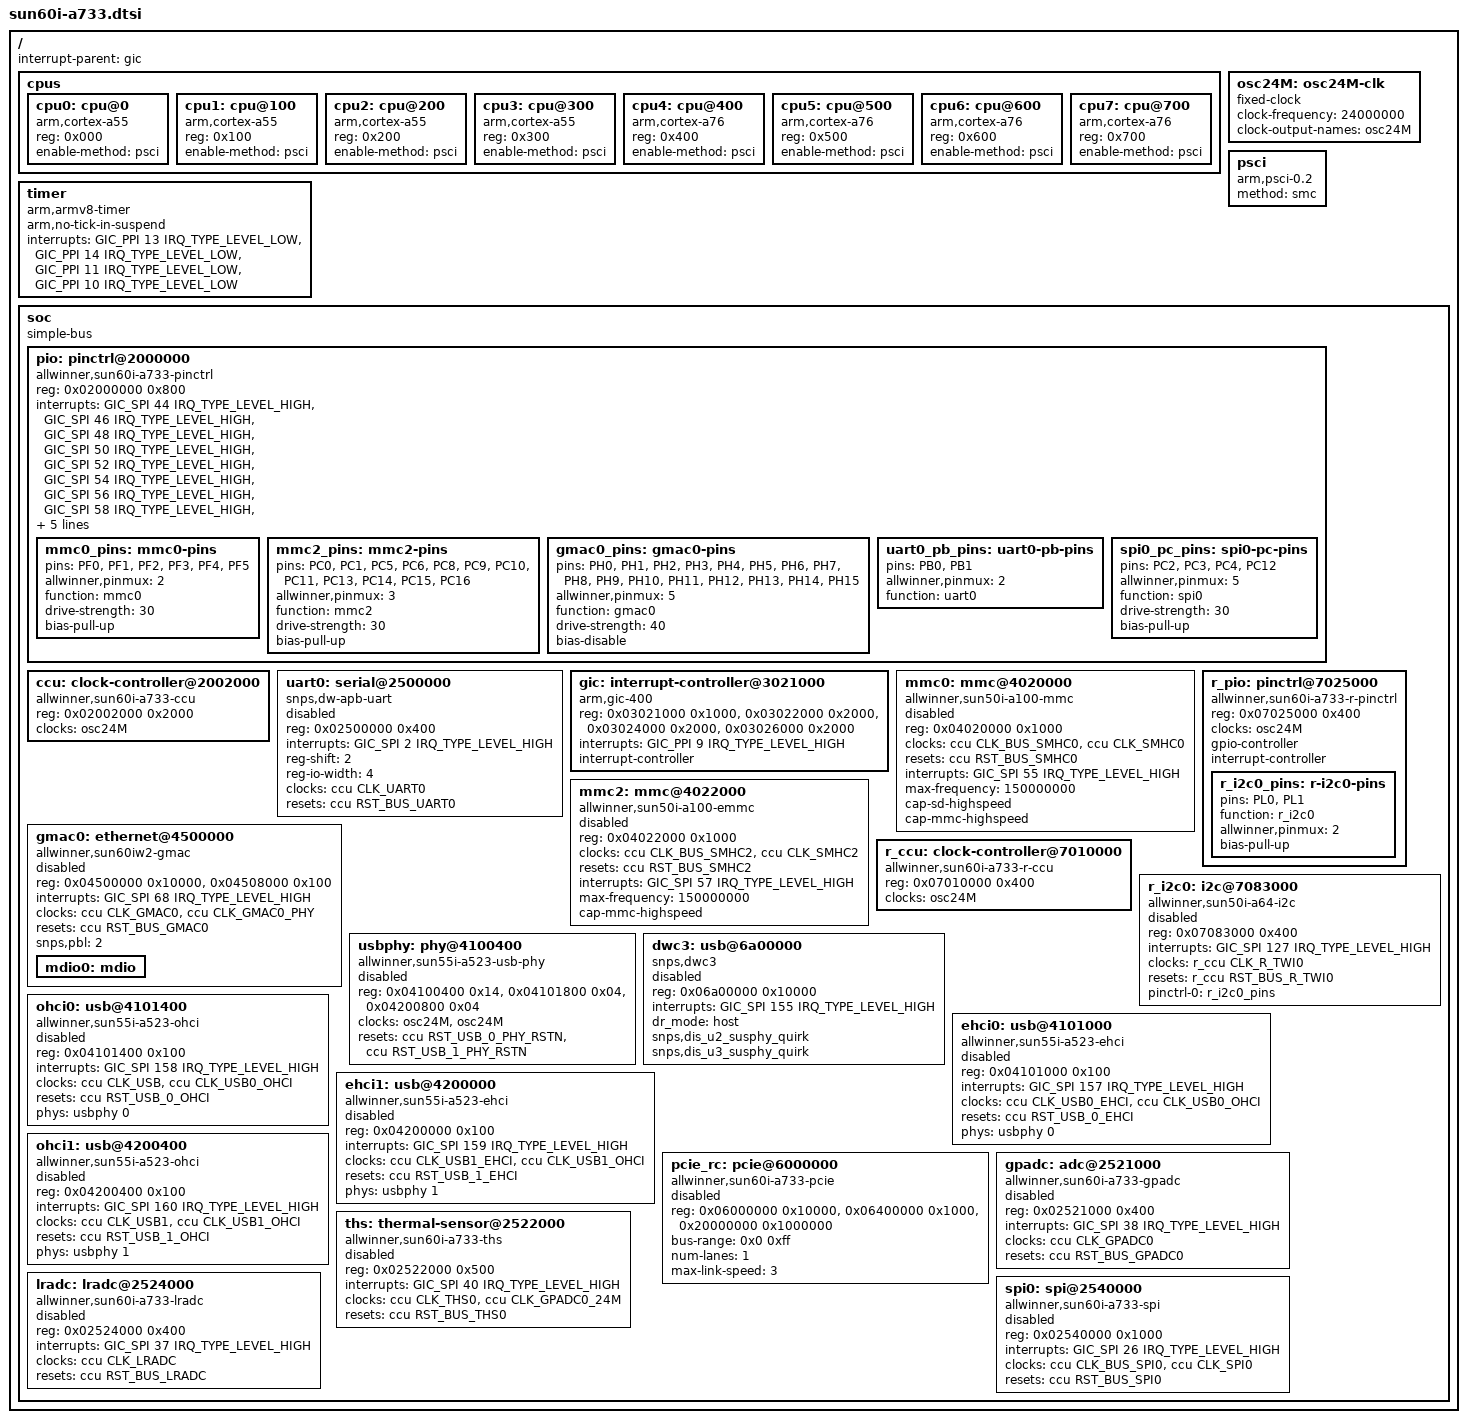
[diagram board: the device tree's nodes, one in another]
// SPDX-License-Identifier: (GPL-2.0-only OR MIT)
/*
 * Copyright (C) 2026 Alastair D'Silva <alastair@d-silva.org>
 */

#include <dt-bindings/interrupt-controller/arm-gic.h>
#include <dt-bindings/clock/sun60i-a733-ccu.h>
#include <dt-bindings/clock/sun60i-a733-r-ccu.h>
#include <dt-bindings/reset/sun60i-a733-ccu.h>
#include <dt-bindings/reset/sun60i-a733-r-ccu.h>

/ {
	interrupt-parent = <&gic>;
	#address-cells = <2>;
	#size-cells = <2>;

	cpus {
		#address-cells = <1>;
		#size-cells = <0>;

		cpu0: cpu@0 {
			compatible = "arm,cortex-a55";
			device_type = "cpu";
			reg = <0x000>;
			enable-method = "psci";
		};

		cpu1: cpu@100 {
			compatible = "arm,cortex-a55";
			device_type = "cpu";
			reg = <0x100>;
			enable-method = "psci";
		};

		cpu2: cpu@200 {
			compatible = "arm,cortex-a55";
			device_type = "cpu";
			reg = <0x200>;
			enable-method = "psci";
		};

		cpu3: cpu@300 {
			compatible = "arm,cortex-a55";
			device_type = "cpu";
			reg = <0x300>;
			enable-method = "psci";
		};

		cpu4: cpu@400 {
			compatible = "arm,cortex-a76";
			device_type = "cpu";
			reg = <0x400>;
			enable-method = "psci";
		};

		cpu5: cpu@500 {
			compatible = "arm,cortex-a76";
			device_type = "cpu";
			reg = <0x500>;
			enable-method = "psci";
		};

		cpu6: cpu@600 {
			compatible = "arm,cortex-a76";
			device_type = "cpu";
			reg = <0x600>;
			enable-method = "psci";
		};

		cpu7: cpu@700 {
			compatible = "arm,cortex-a76";
			device_type = "cpu";
			reg = <0x700>;
			enable-method = "psci";
		};
	};

	osc24M: osc24M-clk {
		#clock-cells = <0>;
		compatible = "fixed-clock";
		clock-frequency = <24000000>;
		clock-output-names = "osc24M";
	};

	psci {
		compatible = "arm,psci-0.2";
		method = "smc";
	};

	timer {
		compatible = "arm,armv8-timer";
		arm,no-tick-in-suspend;
		interrupts = <GIC_PPI 13 IRQ_TYPE_LEVEL_LOW>,
			     <GIC_PPI 14 IRQ_TYPE_LEVEL_LOW>,
			     <GIC_PPI 11 IRQ_TYPE_LEVEL_LOW>,
			     <GIC_PPI 10 IRQ_TYPE_LEVEL_LOW>;
	};

	soc {
		compatible = "simple-bus";
		#address-cells = <1>;
		#size-cells = <1>;
		ranges = <0x0 0x0 0x0 0x40000000>;

		pio: pinctrl@2000000 {
			compatible = "allwinner,sun60i-a733-pinctrl";
			reg = <0x02000000 0x800>;
			interrupts = <GIC_SPI 44 IRQ_TYPE_LEVEL_HIGH>,
				     <GIC_SPI 46 IRQ_TYPE_LEVEL_HIGH>,
				     <GIC_SPI 48 IRQ_TYPE_LEVEL_HIGH>,
				     <GIC_SPI 50 IRQ_TYPE_LEVEL_HIGH>,
				     <GIC_SPI 52 IRQ_TYPE_LEVEL_HIGH>,
				     <GIC_SPI 54 IRQ_TYPE_LEVEL_HIGH>,
				     <GIC_SPI 56 IRQ_TYPE_LEVEL_HIGH>,
				     <GIC_SPI 58 IRQ_TYPE_LEVEL_HIGH>,
				     <GIC_SPI 60 IRQ_TYPE_LEVEL_HIGH>,
				     <GIC_SPI 62 IRQ_TYPE_LEVEL_HIGH>;
			clocks = <&osc24M>;
			gpio-controller;
			#gpio-cells = <3>;
			interrupt-controller;
			#interrupt-cells = <3>;

			mmc0_pins: mmc0-pins {
				pins = "PF0", "PF1", "PF2", "PF3", "PF4", "PF5";
				allwinner,pinmux = <2>;
				function = "mmc0";
				drive-strength = <30>;
				bias-pull-up;
			};

			mmc2_pins: mmc2-pins {
				pins = "PC0", "PC1", "PC5", "PC6", "PC8",
				       "PC9", "PC10", "PC11", "PC13", "PC14",
				       "PC15", "PC16";
				allwinner,pinmux = <3>;
				function = "mmc2";
				drive-strength = <30>;
				bias-pull-up;
			};

			gmac0_pins: gmac0-pins {
				pins = "PH0", "PH1", "PH2", "PH3", "PH4",
				       "PH5", "PH6", "PH7", "PH8", "PH9",
				       "PH10", "PH11", "PH12", "PH13", "PH14", "PH15";
				allwinner,pinmux = <5>;
				function = "gmac0";
				drive-strength = <40>;
				bias-disable;
			};

			uart0_pb_pins: uart0-pb-pins {
				pins = "PB0", "PB1";
				allwinner,pinmux = <2>;
				function = "uart0";
			};

			spi0_pc_pins: spi0-pc-pins {
				pins = "PC2", "PC3", "PC4", "PC12";
				allwinner,pinmux = <5>;
				function = "spi0";
				drive-strength = <30>;
				bias-pull-up;
			};
		};

		ccu: clock-controller@2002000 {
			compatible = "allwinner,sun60i-a733-ccu";
			reg = <0x02002000 0x2000>;
			clocks = <&osc24M>;
			clock-names = "hosc";
			#clock-cells = <1>;
			#reset-cells = <1>;
		};

		uart0: serial@2500000 {
			compatible = "snps,dw-apb-uart";
			reg = <0x02500000 0x400>;
			interrupts = <GIC_SPI 2 IRQ_TYPE_LEVEL_HIGH>;
			reg-shift = <2>;
			reg-io-width = <4>;
			clocks = <&ccu CLK_UART0>;
			resets = <&ccu RST_BUS_UART0>;
			status = "disabled";
		};

		gic: interrupt-controller@3021000 {
			compatible = "arm,gic-400";
			reg = <0x03021000 0x1000>,
			      <0x03022000 0x2000>,
			      <0x03024000 0x2000>,
			      <0x03026000 0x2000>;
			interrupts = <GIC_PPI 9 IRQ_TYPE_LEVEL_HIGH>;
			interrupt-controller;
			#interrupt-cells = <3>;
		};

		mmc0: mmc@4020000 {
			compatible = "allwinner,sun50i-a100-mmc";
			reg = <0x04020000 0x1000>;
			clocks = <&ccu CLK_BUS_SMHC0>, <&ccu CLK_SMHC0>;
			clock-names = "ahb", "mmc";
			resets = <&ccu RST_BUS_SMHC0>;
			reset-names = "ahb";
			interrupts = <GIC_SPI 55 IRQ_TYPE_LEVEL_HIGH>;
			max-frequency = <150000000>;
			cap-sd-highspeed;
			cap-mmc-highspeed;
			status = "disabled";
			#address-cells = <1>;
			#size-cells = <0>;
		};

		mmc2: mmc@4022000 {
			compatible = "allwinner,sun50i-a100-emmc";
			reg = <0x04022000 0x1000>;
			clocks = <&ccu CLK_BUS_SMHC2>, <&ccu CLK_SMHC2>;
			clock-names = "ahb", "mmc";
			resets = <&ccu RST_BUS_SMHC2>;
			reset-names = "ahb";
			interrupts = <GIC_SPI 57 IRQ_TYPE_LEVEL_HIGH>;
			max-frequency = <150000000>;
			cap-mmc-highspeed;
			status = "disabled";
			#address-cells = <1>;
			#size-cells = <0>;
		};

		gmac0: ethernet@4500000 {
			compatible = "allwinner,sun60iw2-gmac", "snps,dwc-qos-ethernet-4.10";
			reg = <0x04500000 0x10000>, <0x04508000 0x100>;
			reg-names = "stmmaceth", "syscon";
			interrupts = <GIC_SPI 68 IRQ_TYPE_LEVEL_HIGH>;
			interrupt-names = "macirq";
			clocks = <&ccu CLK_GMAC0>, <&ccu CLK_GMAC0_PHY>;
			clock-names = "stmmaceth", "pclk";
			resets = <&ccu RST_BUS_GMAC0>;
			reset-names = "stmmaceth";
			snps,pbl = <2>;
			status = "disabled";

			mdio0: mdio {
				#address-cells = <1>;
				#size-cells = <0>;
			};
		};

		r_pio: pinctrl@7025000 {
			compatible = "allwinner,sun60i-a733-r-pinctrl";
			reg = <0x07025000 0x400>;
			clocks = <&osc24M>;
			gpio-controller;
			#gpio-cells = <3>;
			interrupt-controller;
			#interrupt-cells = <3>;

			r_i2c0_pins: r-i2c0-pins {
				pins = "PL0", "PL1";
				function = "r_i2c0";
				allwinner,pinmux = <2>;
				bias-pull-up;
			};
		};

		r_ccu: clock-controller@7010000 {
			compatible = "allwinner,sun60i-a733-r-ccu";
			reg = <0x07010000 0x400>;
			clocks = <&osc24M>;
			clock-names = "hosc";
			#clock-cells = <1>;
			#reset-cells = <1>;
		};

		r_i2c0: i2c@7083000 {
			compatible = "allwinner,sun50i-a64-i2c", "allwinner,sun6i-a31-i2c";
			reg = <0x07083000 0x400>;
			interrupts = <GIC_SPI 127 IRQ_TYPE_LEVEL_HIGH>;
			clocks = <&r_ccu CLK_R_TWI0>;
			resets = <&r_ccu RST_BUS_R_TWI0>;
			pinctrl-names = "default";
			pinctrl-0 = <&r_i2c0_pins>;
			status = "disabled";
			#address-cells = <1>;
			#size-cells = <0>;
		};

		usbphy: phy@4100400 {
			compatible = "allwinner,sun55i-a523-usb-phy";
			reg = <0x04100400 0x14>,
			      <0x04101800 0x04>,
			      <0x04200800 0x04>;
			reg-names = "phy_ctrl",
				    "pmu0",
				    "pmu1";
			clocks = <&osc24M>,
				 <&osc24M>;
			clock-names = "usb0_phy",
				      "usb1_phy";
			resets = <&ccu RST_USB_0_PHY_RSTN>,
				 <&ccu RST_USB_1_PHY_RSTN>;
			reset-names = "usb0_reset",
				      "usb1_reset";
			status = "disabled";
			#phy-cells = <1>;
		};

		dwc3: usb@6a00000 {
			compatible = "snps,dwc3";
			reg = <0x06a00000 0x10000>;
			interrupts = <GIC_SPI 155 IRQ_TYPE_LEVEL_HIGH>;
			dr_mode = "host";
			snps,dis_u2_susphy_quirk;
			snps,dis_u3_susphy_quirk;
			status = "disabled";
		};

		ehci0: usb@4101000 {
			compatible = "allwinner,sun55i-a523-ehci",
				     "generic-ehci";
			reg = <0x04101000 0x100>;
			interrupts = <GIC_SPI 157 IRQ_TYPE_LEVEL_HIGH>;
			clocks = <&ccu CLK_USB0_EHCI>,
				 <&ccu CLK_USB0_OHCI>;
			resets = <&ccu RST_USB_0_EHCI>;
			phys = <&usbphy 0>;
			phy-names = "usb";
			status = "disabled";
		};

		ohci0: usb@4101400 {
			compatible = "allwinner,sun55i-a523-ohci",
				     "generic-ohci";
			reg = <0x04101400 0x100>;
			interrupts = <GIC_SPI 158 IRQ_TYPE_LEVEL_HIGH>;
			clocks = <&ccu CLK_USB>,
				 <&ccu CLK_USB0_OHCI>;
			resets = <&ccu RST_USB_0_OHCI>;
			phys = <&usbphy 0>;
			phy-names = "usb";
			status = "disabled";
		};

		ehci1: usb@4200000 {
			compatible = "allwinner,sun55i-a523-ehci",
				     "generic-ehci";
			reg = <0x04200000 0x100>;
			interrupts = <GIC_SPI 159 IRQ_TYPE_LEVEL_HIGH>;
			clocks = <&ccu CLK_USB1_EHCI>,
				 <&ccu CLK_USB1_OHCI>;
			resets = <&ccu RST_USB_1_EHCI>;
			phys = <&usbphy 1>;
			phy-names = "usb";
			status = "disabled";
		};

		ohci1: usb@4200400 {
			compatible = "allwinner,sun55i-a523-ohci",
				     "generic-ohci";
			reg = <0x04200400 0x100>;
			interrupts = <GIC_SPI 160 IRQ_TYPE_LEVEL_HIGH>;
			clocks = <&ccu CLK_USB1>,
				 <&ccu CLK_USB1_OHCI>;
			resets = <&ccu RST_USB_1_OHCI>;
			phys = <&usbphy 1>;
			phy-names = "usb";
			status = "disabled";
		};

		pcie_rc: pcie@6000000 {
			compatible = "allwinner,sun60i-a733-pcie",
				     "allwinner,sunxi-pcie-v300-rc",
				     "snps,dw-pcie";
			reg = <0x06000000 0x10000>,
			      <0x06400000 0x1000>,
			      <0x20000000 0x1000000>;
			reg-names = "dbi", "app", "config";
			#address-cells = <3>;
			#size-cells = <2>;
			device_type = "pci";
			bus-range = <0x0 0xff>;
			ranges = <0x81000000 0x0 0x21000000 0x21000000 0x0 0x01000000>,
				 <0x82000000 0x0 0x22000000 0x22000000 0x0 0x0e000000>;
			num-lanes = <1>;
			max-link-speed = <3>;
			status = "disabled";
		};

		gpadc: adc@2521000 {
			compatible = "allwinner,sun60i-a733-gpadc",
				     "allwinner,sun55i-a523-gpadc",
				     "allwinner,sun20i-d1-gpadc";
			reg = <0x02521000 0x400>;
			interrupts = <GIC_SPI 38 IRQ_TYPE_LEVEL_HIGH>;
			clocks = <&ccu CLK_GPADC0>;
			resets = <&ccu RST_BUS_GPADC0>;
			#io-channel-cells = <1>;
			status = "disabled";
		};

		ths: thermal-sensor@2522000 {
			compatible = "allwinner,sun60i-a733-ths",
				     "allwinner,sun50i-h616-ths";
			reg = <0x02522000 0x500>;
			interrupts = <GIC_SPI 40 IRQ_TYPE_LEVEL_HIGH>;
			clocks = <&ccu CLK_THS0>, <&ccu CLK_GPADC0_24M>;
			clock-names = "bus", "gpadc";
			resets = <&ccu RST_BUS_THS0>;
			#thermal-sensor-cells = <1>;
			status = "disabled";
		};

		lradc: lradc@2524000 {
			compatible = "allwinner,sun60i-a733-lradc",
				     "allwinner,sun55i-a523-lradc",
				     "allwinner,sun50i-h616-lradc";
			reg = <0x02524000 0x400>;
			interrupts = <GIC_SPI 37 IRQ_TYPE_LEVEL_HIGH>;
			clocks = <&ccu CLK_LRADC>;
			resets = <&ccu RST_BUS_LRADC>;
			status = "disabled";
		};

		spi0: spi@2540000 {
			compatible = "allwinner,sun60i-a733-spi",
				     "allwinner,sun50i-r329-spi";
			reg = <0x02540000 0x1000>;
			interrupts = <GIC_SPI 26 IRQ_TYPE_LEVEL_HIGH>;
			clocks = <&ccu CLK_BUS_SPI0>, <&ccu CLK_SPI0>;
			clock-names = "ahb", "mod";
			resets = <&ccu RST_BUS_SPI0>;
			#address-cells = <1>;
			#size-cells = <0>;
			status = "disabled";
		};
	};
};
